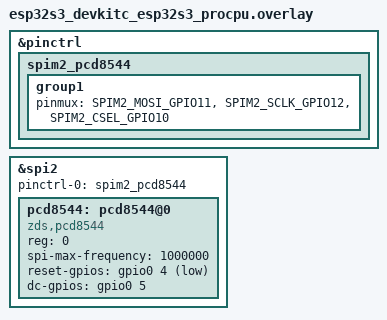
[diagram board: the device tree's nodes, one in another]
/*
 * ESP32-S3-DevKitC-1: SPI2 (GPSPI2) bus wired to a Nokia 5110
 * (PCD8544 controller) monochrome LCD.
 *
 * The module has no MISO line - it's write-only - so only MOSI, SCLK,
 * and hardware CS0 are configured here (compare with Lab 03, which
 * needed MISO for its loopback test).
 *
 * RST and DC are plain GPIOs, not part of the SPI pinctrl group -
 * this mirrors how Zephyr's own SPI display bindings (e.g. the
 * mipi-dbi-spi binding used by several official display drivers)
 * declare "reset-gpios" / "dc-gpios" as ordinary devicetree GPIO
 * properties alongside the SPI bus connection.
 *
 * spi-max-frequency is a conservative 1 MHz (PCD8544's datasheet
 * ceiling is around 4 MHz) - see the comment in main.c for why.
 */

#include <zephyr/dt-bindings/gpio/gpio.h>

&pinctrl {
    spim2_pcd8544: spim2_pcd8544 {
        group1 {
            pinmux = <SPIM2_MOSI_GPIO11>, <SPIM2_SCLK_GPIO12>, <SPIM2_CSEL_GPIO10>;
        };
    };
};

&spi2 {
    #address-cells = <1>;
    #size-cells = <0>;
    status = "okay";
    pinctrl-0 = <&spim2_pcd8544>;
    pinctrl-names = "default";

    pcd8544: pcd8544@0 {
        compatible = "zds,pcd8544";
        reg = <0>;
        spi-max-frequency = <1000000>;

        /* Active low: physically pulled low to reset the controller. */
        reset-gpios = <&gpio0 4 GPIO_ACTIVE_LOW>;
        /* Active high: driven low for a command byte, high for data. */
        dc-gpios = <&gpio0 5 GPIO_ACTIVE_HIGH>;
    };
};
